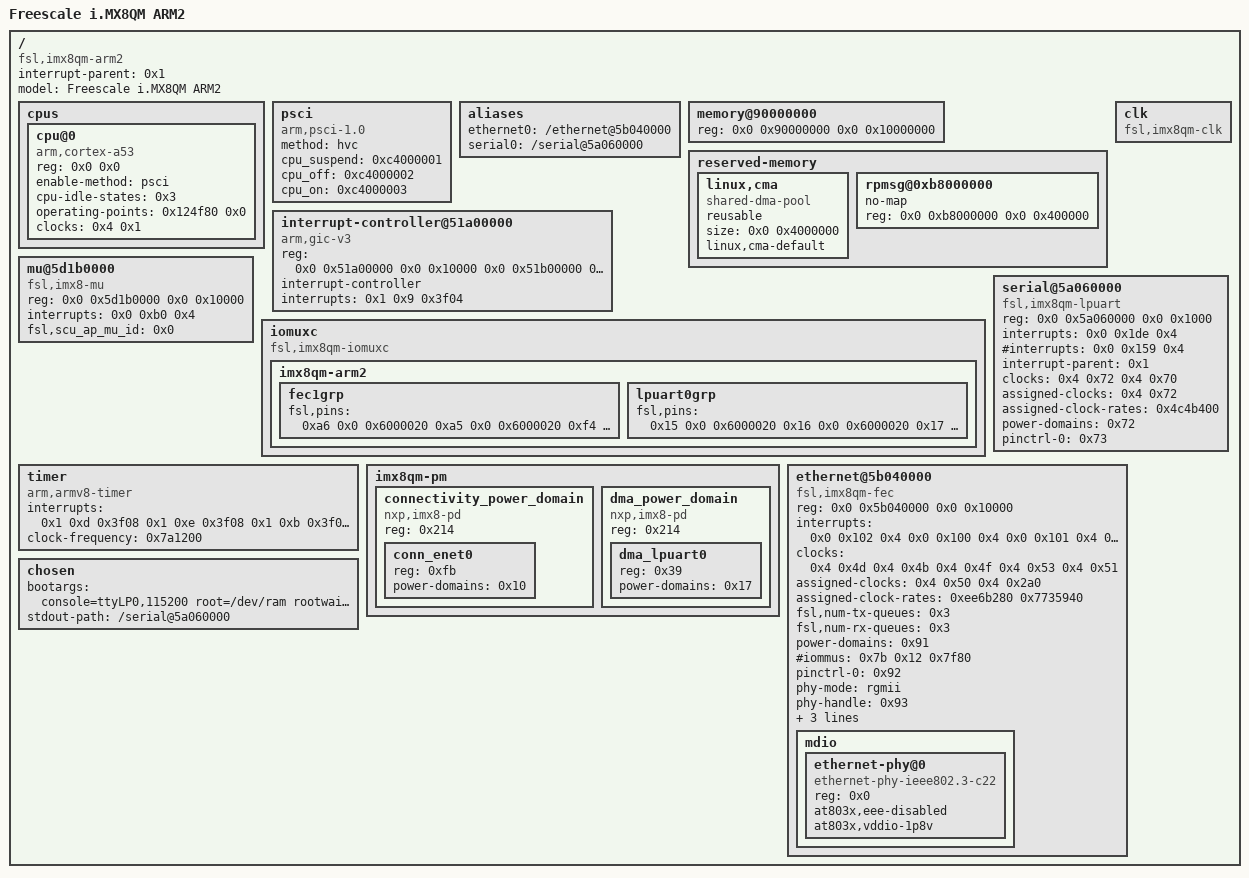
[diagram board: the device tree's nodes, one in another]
/dts-v1/;

/*
 * Copyright (C) 2016 Freescale Semiconductor, Inc.
 * Copyright 2017 NXP
 * Copyright 2018, DornerWorks
 *
 * This program is free software; you can redistribute it and/or
 * modify it under the terms of the GNU General Public License
 * as published by the Free Software Foundation; either version 2
 * of the License, or (at your option) any later version.
 *
 * This program is distributed in the hope that it will be useful,
 * but WITHOUT ANY WARRANTY; without even the implied warranty of
 * MERCHANTABILITY or FITNESS FOR A PARTICULAR PURPOSE.  See the
 * GNU General Public License for more details.
 */

/ {
	compatible = "fsl,imx8qm-arm2", "fsl,imx8qm";
	interrupt-parent = <0x1>;
	#address-cells = <0x2>;
	#size-cells = <0x2>;
	model = "Freescale i.MX8QM ARM2";

	cpus {
		#address-cells = <0x2>;
		#size-cells = <0x0>;

		cpu@0 {
			device_type = "cpu";
			compatible = "arm,cortex-a53";
			reg = <0x0 0x0>;
			enable-method = "psci";
			cpu-idle-states = <0x3>;
			operating-points = <0x124f80 0x0>;
			clocks = <0x4 0x1>;
		};
	};

	psci {
		compatible = "arm,psci-1.0";
		method = "hvc";
		cpu_suspend = <0xc4000001>;
		cpu_off = <0xc4000002>;
		cpu_on = <0xc4000003>;
	};

	aliases {
		ethernet0 = "/ethernet@5b040000";
		serial0 = "/serial@5a060000";
	};

	memory@90000000 {
		device_type = "memory";
		reg = <0x0 0x90000000 0x0 0x10000000>;
	};

	reserved-memory {
		#address-cells = <0x2>;
		#size-cells = <0x2>;
		ranges;

		linux,cma {
			compatible = "shared-dma-pool";
			reusable;
			size = <0x0 0x4000000>;
			linux,cma-default;
		};

		rpmsg@0xb8000000 {
			no-map;
			reg = <0x0 0xb8000000 0x0 0x400000>;
		};
	};

	interrupt-controller@51a00000 {
		compatible = "arm,gic-v3";
		reg = <0x0 0x51a00000 0x0 0x10000 0x0 0x51b00000 0x0 0xc0000>;
		#interrupt-cells = <0x3>;
		interrupt-controller;
		interrupts = <0x1 0x9 0x3f04>;
		linux,phandle = <0x1>;
		phandle = <0x1>;
	};

	mu@5d1b0000 {
		compatible = "fsl,imx8-mu";
		reg = <0x0 0x5d1b0000 0x0 0x10000>;
		interrupts = <0x0 0xb0 0x4>;
		fsl,scu_ap_mu_id = <0x0>;
		status = "okay";
	};

	clk {
		compatible = "fsl,imx8qm-clk";
		#clock-cells = <0x1>;
		linux,phandle = <0x4>;
		phandle = <0x4>;
	};

	iomuxc {
		compatible = "fsl,imx8qm-iomuxc";

		imx8qm-arm2 {
			fec1grp {
				fsl,pins = <0xa6 0x0 0x6000020 0xa5 0x0 0x6000020 0xf4 0x0 0x6000020 0xf3 0x0 0x6000020 0xf5 0x0 0x6000020 0xf6 0x0 0x6000020 0xf7 0x0 0x6000020 0xf8 0x0 0x6000020 0xf9 0x0 0x6000020 0xfa 0x0 0x6000020 0xfb 0x0 0x6000020 0xfc 0x0 0x6000020 0xfd 0x0 0x6000020 0xfe 0x0 0x6000020>;
				linux,phandle = <0x92>;
				phandle = <0x92>;
			};

			lpuart0grp {
				fsl,pins = <0x15 0x0 0x6000020 0x16 0x0 0x6000020 0x17 0x0 0x6000020 0x18 0x0 0x6000020>;
				linux,phandle = <0x73>;
				phandle = <0x73>;
			};
		};
	};

	timer {
		compatible = "arm,armv8-timer";
		interrupts = <0x1 0xd 0x3f08 0x1 0xe 0x3f08 0x1 0xb 0x3f08 0x1 0xa 0x3f08>;
		clock-frequency = <0x7a1200>;
	};

	imx8qm-pm {
		#address-cells = <0x1>;
		#size-cells = <0x0>;

		connectivity_power_domain {
			compatible = "nxp,imx8-pd";
			reg = <0x214>;
			#power-domain-cells = <0x0>;
			#address-cells = <0x1>;
			#size-cells = <0x0>;
			linux,phandle = <0x10>;
			phandle = <0x10>;

			conn_enet0 {
				reg = <0xfb>;
				#power-domain-cells = <0x0>;
				power-domains = <0x10>;
				linux,phandle = <0x91>;
				phandle = <0x91>;
			};
		};

		dma_power_domain {
			compatible = "nxp,imx8-pd";
			reg = <0x214>;
			#power-domain-cells = <0x0>;
			#address-cells = <0x1>;
			#size-cells = <0x0>;
			linux,phandle = <0x17>;
			phandle = <0x17>;

			dma_lpuart0 {
				reg = <0x39>;
				#power-domain-cells = <0x0>;
				power-domains = <0x17>;
				linux,phandle = <0x72>;
				phandle = <0x72>;
			};
		};
	};

	serial@5a060000 {
		compatible = "fsl,imx8qm-lpuart";
		reg = <0x0 0x5a060000 0x0 0x1000>;
		interrupts = <0x0 0x1de 0x4>;
		#interrupts = <0x0 0x159 0x4>;
		interrupt-parent = <0x1>;
		clocks = <0x4 0x72 0x4 0x70>;
		clock-names = "per", "ipg";
		assigned-clocks = <0x4 0x72>;
		assigned-clock-rates = <0x4c4b400>;
		power-domains = <0x72>;
		status = "okay";
		pinctrl-names = "default";
		pinctrl-0 = <0x73>;
	};

	ethernet@5b040000 {
		compatible = "fsl,imx8qm-fec";
		reg = <0x0 0x5b040000 0x0 0x10000>;
		interrupts = <0x0 0x102 0x4 0x0 0x100 0x4 0x0 0x101 0x4 0x0 0x103 0x4>;
		clocks = <0x4 0x4d 0x4 0x4b 0x4 0x4f 0x4 0x53 0x4 0x51>;
		clock-names = "ipg", "ahb", "enet_clk_ref", "ptp", "enet_2x_txclk";
		assigned-clocks = <0x4 0x50 0x4 0x2a0>;
		assigned-clock-rates = <0xee6b280 0x7735940>;
		fsl,num-tx-queues = <0x3>;
		fsl,num-rx-queues = <0x3>;
		power-domains = <0x91>;
		#iommus = <0x7b 0x12 0x7f80>;
		status = "okay";
		pinctrl-names = "default";
		pinctrl-0 = <0x92>;
		phy-mode = "rgmii";
		phy-handle = <0x93>;
		fsl,magic-packet;
		fsl,rgmii_txc_dly;
		fsl,rgmii_rxc_dly;

		mdio {
			#address-cells = <0x1>;
			#size-cells = <0x0>;

			ethernet-phy@0 {
				compatible = "ethernet-phy-ieee802.3-c22";
				reg = <0x0>;
				at803x,eee-disabled;
				at803x,vddio-1p8v;
				linux,phandle = <0x93>;
				phandle = <0x93>;
			};
		};
	};

	chosen {
		bootargs = "console=ttyLP0,115200 root=/dev/ram rootwait rw earlycon=lpuart32,0x5a060000,115200 clk_ignore_unused maxcpus=0";
		stdout-path = "/serial@5a060000";
	};
};
